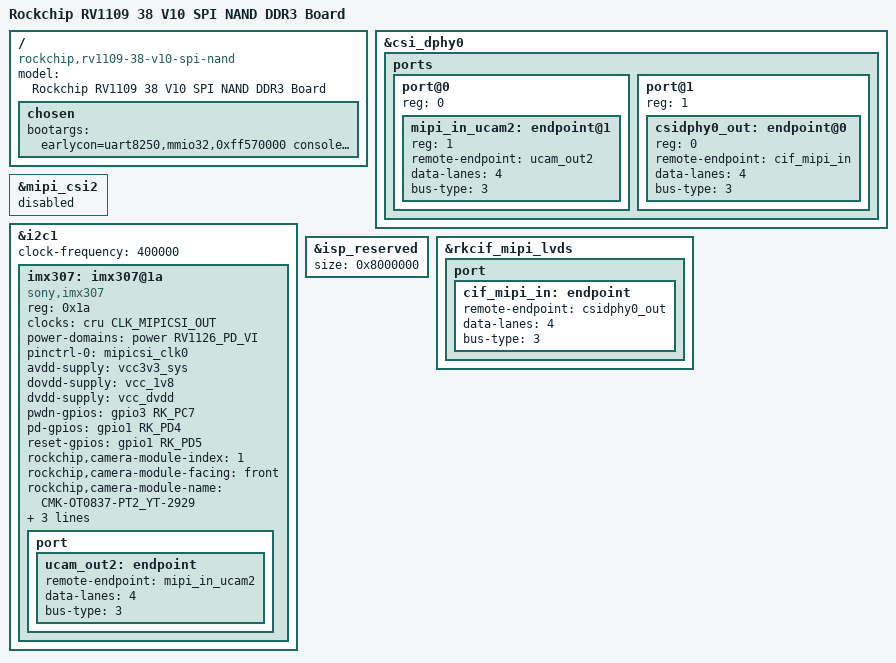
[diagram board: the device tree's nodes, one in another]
// SPDX-License-Identifier: (GPL-2.0+ OR MIT)
/*
 * Copyright (c) 2020 Rockchip Electronics Co., Ltd.
 */

/dts-v1/;

#include "rv11xx-owl-38ipc-v10.dtsi"

/ {
	model = "Rockchip RV1109 38 V10 SPI NAND DDR3 Board";
	compatible = "rockchip,rv1109-38-v10-spi-nand", "rockchip,rv1109";

	chosen {
		bootargs = "earlycon=uart8250,mmio32,0xff570000 console=ttyFIQ0 ubi.mtd=2 root=ubi0:rootfs rootfstype=ubifs snd_aloop.index=7";
	};
};

&csi_dphy0 {
	status = "okay";

	ports {
		#address-cells = <1>;
		#size-cells = <0>;
		port@0 {
			reg = <0>;
			#address-cells = <1>;
			#size-cells = <0>;

			mipi_in_ucam2: endpoint@1 {
				reg = <1>;
				remote-endpoint = <&ucam_out2>;
				data-lanes = <4>;
				bus-type = <3>;
			};
		};
		port@1 {
			reg = <1>;
			#address-cells = <1>;
			#size-cells = <0>;

			csidphy0_out: endpoint@0 {
				reg = <0>;
				remote-endpoint = <&cif_mipi_in>;
				data-lanes = <4>;
				bus-type = <3>;
			};
		};
	};
};

&mipi_csi2 {
	status = "disabled";
};

&i2c1 {
	status = "okay";
	clock-frequency = <400000>;

	/delete-node/ imx415@1a ;

	imx307: imx307@1a {
		compatible = "sony,imx307";
		reg = <0x1a>;
        clocks = <&cru CLK_MIPICSI_OUT>;
        clock-names = "xvclk";
        power-domains = <&power RV1126_PD_VI>;
        pinctrl-names = "rockchip,camera_default";
        pinctrl-0 = <&mipicsi_clk0>;
		avdd-supply = <&vcc3v3_sys>;
		dovdd-supply = <&vcc_1v8>;
		dvdd-supply = <&vcc_dvdd>;
        pwdn-gpios = <&gpio3 RK_PC7 GPIO_ACTIVE_HIGH>;
        pd-gpios = <&gpio1 RK_PD4 GPIO_ACTIVE_HIGH>;
		reset-gpios = <&gpio1 RK_PD5 GPIO_ACTIVE_HIGH>;
		rockchip,camera-module-index = <1>;
		rockchip,camera-module-facing = "front";
		rockchip,camera-module-name = "CMK-OT0837-PT2_YT-2929";
		rockchip,camera-module-lens-name = "UNV-40IRC-2M-F20";
		ir-cut = <&cam_ircut0>;
		port {
			ucam_out2: endpoint {
				remote-endpoint = <&mipi_in_ucam2>;
				data-lanes = <4>;
				bus-type = <3>;
			};
		};
	};
};

&isp_reserved {
	size = <0x8000000>;
};

&rkcif_mipi_lvds {
	status = "okay";

	port {
		/* MIPI CSI-2 endpoint */
		cif_mipi_in: endpoint {
			remote-endpoint = <&csidphy0_out>;
			data-lanes = <4>;
			bus-type = <3>;
		};
	};
};
